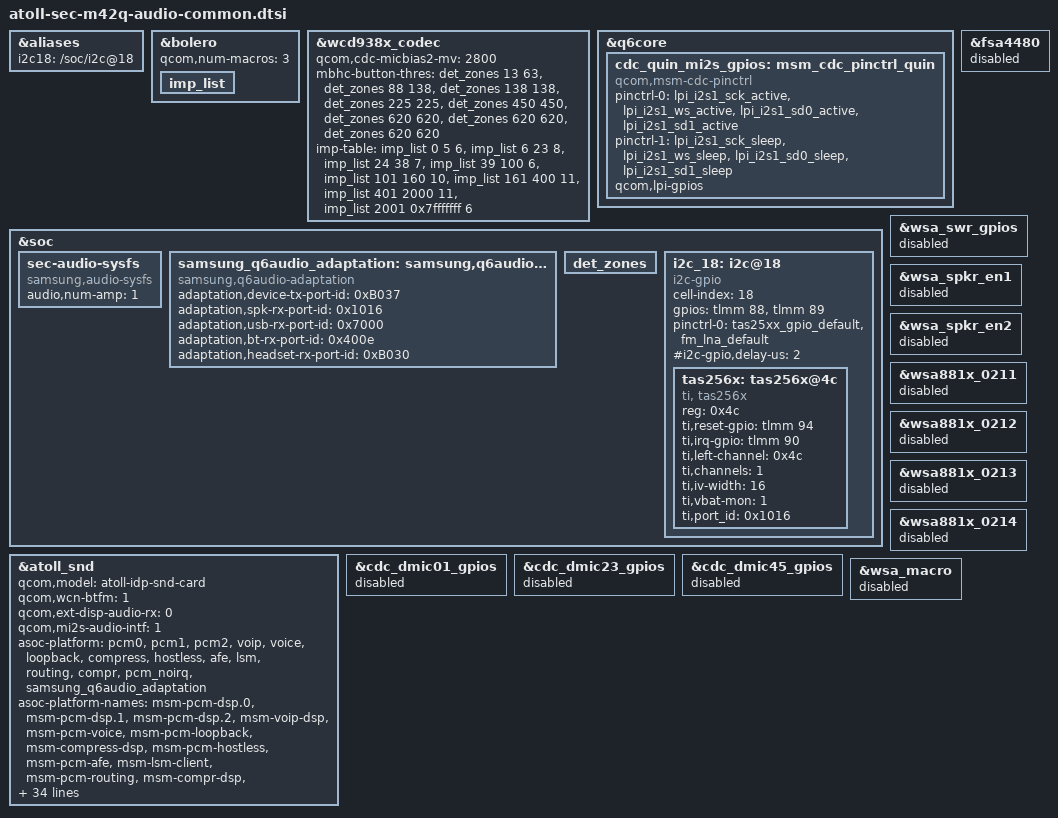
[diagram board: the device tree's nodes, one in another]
/* Copyright (c) 2019, The Linux Foundation. All rights reserved.
 *
 * This program is free software; you can redistribute it and/or modify
 * it under the terms of the GNU General Public License version 2 and
 * only version 2 as published by the Free Software Foundation.
 *
 * This program is distributed in the hope that it will be useful,
 * but WITHOUT ANY WARRANTY; without even the implied warranty of
 * MERCHANTABILITY or FITNESS FOR A PARTICULAR PURPOSE.  See the
 * GNU General Public License for more details.
 */

&aliases {
	i2c18 = "/soc/i2c@18";
};

&bolero {
	qcom,num-macros = <3>;
	imp_list: imp_list {
		#list-imp-cells = <3>;
	};
};

&wcd938x_codec {
	qcom,cdc-micbias2-mv = <2800>;
	mbhc-button-thres = <&det_zones 13 63>,
		 <&det_zones 88 138>,
		 <&det_zones 138 138>,
		 <&det_zones 225 225>,
		 <&det_zones 450 450>,
		 <&det_zones 620 620>,
		 <&det_zones 620 620>,
		 <&det_zones 620 620>;
	imp-table = <&imp_list 0 5 6>,
			 <&imp_list 6 23 8>,
			 <&imp_list 24 38 7>,
			 <&imp_list 39 100 6>,
			 <&imp_list 101 160 10>,
			 <&imp_list 161 400 11>,
			 <&imp_list 401 2000 11>,
			 <&imp_list 2001 0x7fffffff 6>;
};

&q6core {
	cdc_quin_mi2s_gpios: msm_cdc_pinctrl_quin {
		compatible = "qcom,msm-cdc-pinctrl";
		pinctrl-names = "aud_active", "aud_sleep";
		pinctrl-0 = <&lpi_i2s1_sck_active &lpi_i2s1_ws_active
				 &lpi_i2s1_sd0_active &lpi_i2s1_sd1_active>;
		pinctrl-1 = <&lpi_i2s1_sck_sleep &lpi_i2s1_ws_sleep
				 &lpi_i2s1_sd0_sleep &lpi_i2s1_sd1_sleep>;
		qcom,lpi-gpios;
	};
};

&soc {
	sec-audio-sysfs {
		compatible = "samsung,audio-sysfs";
		status = "okay";
		audio,num-amp = <1>;
	};

	samsung_q6audio_adaptation: samsung,q6audio-adaptation {
		compatible = "samsung,q6audio-adaptation";
		adaptation,device-tx-port-id = <0xB037>;
		adaptation,spk-rx-port-id = <0x1016>;
		adaptation,usb-rx-port-id = <0x7000>;
		adaptation,bt-rx-port-id = <0x400e>;
		adaptation,headset-rx-port-id = <0xB030>;
	};

	det_zones: det_zones {
		#list-det-cells = <2>;
	};

	i2c_18: i2c@18 { /* SW I2C */
		status = "ok";

		cell-index = <18>;
		compatible = "i2c-gpio";
		gpios = <&tlmm 88 0 /* sda */
			 &tlmm 89 0 /* scl */
		>;
		pinctrl-names = "default";
		pinctrl-0 = <&tas25xx_gpio_default &fm_lna_default>;
		#i2c-gpio,delay-us = <2>;
		#address-cells = <1>;
		#size-cells = <0>;

		tas256x:tas256x@4c {
			#sound-dai-cells = <0>;
			compatible = "ti, tas256x";
			status = "ok";
			reg = <0x4c>;
			ti,reset-gpio = <&tlmm 94 0>;
			ti,irq-gpio = <&tlmm 90 0>;
			ti,left-channel = <0x4c>;
			ti,channels = <1>; /* channel number */
			ti,iv-width = <16>;
			ti,vbat-mon = <1>;
			ti,port_id = <0x1016>; /* Rx port ID use for Qcom platform */
		};
	};
};

&atoll_snd {
	qcom,model = "atoll-idp-snd-card";
	qcom,wcn-btfm = <1>;
	qcom,ext-disp-audio-rx = <0>;
	qcom,mi2s-audio-intf = <1>;
	asoc-platform = <&pcm0>, <&pcm1>, <&pcm2>, <&voip>, <&voice>,
			<&loopback>, <&compress>, <&hostless>,
			<&afe>, <&lsm>, <&routing>, <&compr>,
			<&pcm_noirq>, <&samsung_q6audio_adaptation>;
	asoc-platform-names = "msm-pcm-dsp.0", "msm-pcm-dsp.1",
			"msm-pcm-dsp.2", "msm-voip-dsp",
			"msm-pcm-voice", "msm-pcm-loopback",
			"msm-compress-dsp", "msm-pcm-hostless",
			"msm-pcm-afe", "msm-lsm-client",
			"msm-pcm-routing", "msm-compr-dsp",
			"msm-pcm-dsp-noirq", "q6audio-adaptation";
	qcom,audio-routing =
		"AMIC1", "MIC BIAS1",
		"MIC BIAS1", "Analog Mic1",
		"AMIC2", "MIC BIAS2",
		"MIC BIAS2", "Analog Mic2",
		"AMIC3", "MIC BIAS3",
		"MIC BIAS3", "Analog Mic3",
		"AMIC4", "MIC BIAS3",
		"MIC BIAS3", "Analog Mic4",
		"AMIC5", "MIC BIAS4",
		"MIC BIAS4", "Analog Mic5",
		"IN1_HPHL", "HPHL_OUT",
		"IN2_HPHR", "HPHR_OUT",
		"TX SWR_ADC0", "ADC1_OUTPUT",
		"TX SWR_ADC1", "ADC2_OUTPUT",
		"TX SWR_ADC2", "ADC3_OUTPUT",
		"TX SWR_ADC3", "ADC4_OUTPUT",
		"RX_TX DEC0_INP", "TX DEC0 MUX",
		"RX_TX DEC1_INP", "TX DEC1 MUX",
		"RX_TX DEC2_INP", "TX DEC2 MUX",
		"RX_TX DEC3_INP", "TX DEC3 MUX",
		"VA_AIF1 CAP", "VA_SWR_CLK",
		"VA_AIF2 CAP", "VA_SWR_CLK",
		"VA_AIF3 CAP", "VA_SWR_CLK",
		"VA SWR_ADC0", "ADC1_OUTPUT",
		"VA SWR_ADC1", "ADC2_OUTPUT",
		"VA SWR_ADC2", "ADC3_OUTPUT",
		"VA SWR_ADC3", "ADC4_OUTPUT";

	qcom,msm-mbhc-hs-mic-max-threshold-mv = <9999>;
	qcom,msm-mbhc-hs-mic-min-threshold-mv = <640>;
	qcom,msm-mbhc-gnd-swh = <0>;
	qcom,cdc-dmic01-gpios = <>;
	qcom,cdc-dmic23-gpios = <>;
	qcom,cdc-dmic45-gpios = <>;
	qcom,quin-mi2s-gpios = <&cdc_quin_mi2s_gpios>;
	asoc-codec  = <&stub_codec>, <&bolero>;
	asoc-codec-names = "msm-stub-codec.1", "bolero_codec";
	qcom,wsa-max-devs = <0>;
	qcom,wsa-devs = <0>;
	qcom,msm_audio_ssr_devs = <&audio_apr>, <&q6core>,
				  <&lpi_tlmm>, <&bolero>;
	fsa4480-i2c-handle = <>;
	qcom,fm-lna-gpios = <&tlmm 84 0>;
};

&fsa4480 {
	status = "disabled";
};
&wsa_swr_gpios {
	status = "disabled";
};
&wsa_spkr_en1 {
	status = "disabled";
};
&wsa_spkr_en2 {
	status = "disabled";
};
&wsa881x_0211 {
	status = "disabled";
};
&wsa881x_0212 {
	status = "disabled";
};
&wsa881x_0213 {
	status = "disabled";
};
&wsa881x_0214 {
	status = "disabled";
};
&cdc_dmic01_gpios {
	status = "disabled";
};
&cdc_dmic23_gpios {
	status = "disabled";
};
&cdc_dmic45_gpios {
	status = "disabled";
};
&wsa_swr_gpios {
	status = "disabled";
};
&wsa_macro {
	status = "disabled";
};
